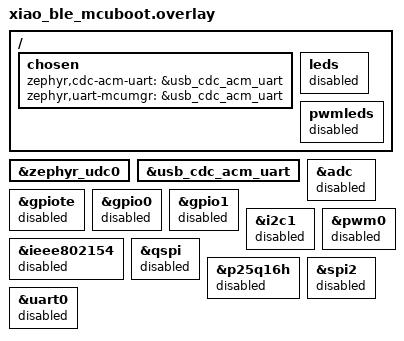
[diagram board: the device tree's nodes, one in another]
/*
 * MCUboot board overlay for the XIAO nRF52840 (mcuboot sysbuild image).
 *
 * MCUboot's serial recovery runs over the USB CDC ACM UART, so a board whose
 * primary slot is empty or invalid can still be given an image over USB with no
 * SWD probe attached. Everything the bootloader does not need is disabled to
 * keep it inside its flash budget.
 */
/ {
	chosen {
		zephyr,cdc-acm-uart = &usb_cdc_acm_uart;
		zephyr,uart-mcumgr = &usb_cdc_acm_uart;
	};
	leds {
		status = "disabled";
	};
	pwmleds {
		status = "disabled";
	};
};
&zephyr_udc0 {
	status = "okay";
};
/*
 * NCS 2.9.2 renamed the xiao_ble USB-CDC node label cdc_acm_uart0 ->
 * usb_cdc_acm_uart (xiao_ble_common.dtsi). The bootloader's serial recovery uses
 * this CDC UART (chosen above), so leave the board's usb_cdc_acm_uart enabled
 * rather than disabling it and pointing at a now-undefined cdc_acm_uart0.
 */
&usb_cdc_acm_uart {
	status = "okay";
};
&adc {
	status = "disabled";
};
&gpiote {
	status = "disabled";
};
&gpio0 {
	status = "disabled";
};
&gpio1 {
	status = "disabled";
};
&i2c1 {
	status = "disabled";
};
&ieee802154 {
	status = "disabled";
};
&pwm0 {
	status = "disabled";
};
&qspi {
	status = "disabled";
};
&p25q16h {
	status = "disabled";
};
&spi2 {
	status = "disabled";
};
&uart0 {
	status = "disabled";
};
